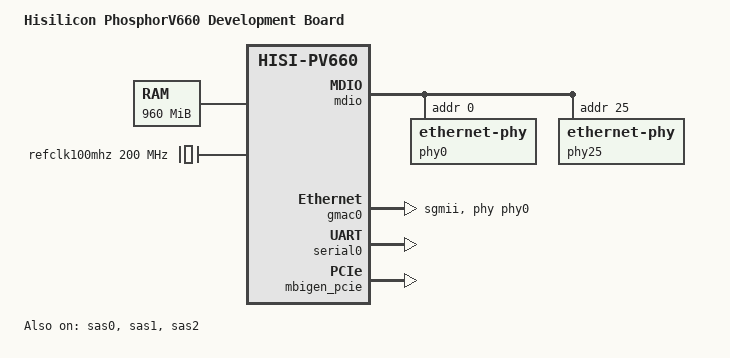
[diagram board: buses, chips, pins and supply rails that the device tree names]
/**
 * dts file for Hisilicon Hi1610
 *
 * Copyright (C) 2014, Hisilicon Ltd.
 *
 * This program is free software; you can redistribute it and/or modify
 * it under the terms of the GNU General Public License version 2 as
 * publishhed by the Free Software Foundation.
 *
 */

/dts-v1/;

/memreserve/ 0x00000000 0x00010000;

/ {
	#address-cells = <2>;
	#size-cells = <2>;
	model = "Hisilicon PhosphorV660 Development Board";
	compatible = "hisilicon,hip05-D02", "hisilicon,hisi-pv660";
	interrupt-parent = <&gic>;

	cpus {
		#address-cells = <1>;
		#size-cells = <0>;

		cpu@10000 {
			device_type = "cpu";
			compatible = "arm,armv8";
			reg = <0x10000>;
			enable-method = "spin-table";
			cpu-release-addr = <0x0 0xfff8>;
		};

		cpu@10001 {
			device_type = "cpu";
			compatible = "arm,armv8";
			reg = <0x10001>;
			enable-method = "spin-table";
			cpu-release-addr = <0x0 0xfff8>;
		};

		cpu@10002 {
			device_type = "cpu";
			compatible = "arm,armv8";
			reg = <0x10002>;
			enable-method = "spin-table";
			cpu-release-addr = <0x0 0xfff8>;
		};

		cpu@10003 {
			device_type = "cpu";
			compatible = "arm,armv8";
			reg = <0x10003>;
			enable-method = "spin-table";
			cpu-release-addr = <0x0 0xfff8>;
		};

		cpu@10100 {
			device_type = "cpu";
			compatible = "arm,armv8";
			reg = <0x10100>;
			enable-method = "spin-table";
			cpu-release-addr = <0x0 0xfff8>;
		};

		cpu@10101 {
			device_type = "cpu";
			compatible = "arm,armv8";
			reg = <0x10101>;
			enable-method = "spin-table";
			cpu-release-addr = <0x0 0xfff8>;
		};

		cpu@10102 {
			device_type = "cpu";
			compatible = "arm,armv8";
			reg = <0x10102>;
			enable-method = "spin-table";
			cpu-release-addr = <0x0 0xfff8>;
		};

		cpu@10103 {
			device_type = "cpu";
			compatible = "arm,armv8";
			reg = <0x10103>;
			enable-method = "spin-table";
			cpu-release-addr = <0x0 0xfff8>;
		};

		cpu@10200 {
			device_type = "cpu";
			compatible = "arm,armv8";
			reg = <0x10200>;
			enable-method = "spin-table";
			cpu-release-addr = <0x0 0xfff8>;
		};

		cpu@10201 {
			device_type = "cpu";
			compatible = "arm,armv8";
			reg = <0x10201>;
			enable-method = "spin-table";
			cpu-release-addr = <0x0 0xfff8>;
		};

		cpu@10202 {
			device_type = "cpu";
			compatible = "arm,armv8";
			reg = <0x10202>;
			enable-method = "spin-table";
			cpu-release-addr = <0x0 0xfff8>;
		};

		cpu@10203 {
			device_type = "cpu";
			compatible = "arm,armv8";
			reg = <0x10203>;
			enable-method = "spin-table";
			cpu-release-addr = <0x0 0xfff8>;
		};

		cpu@10300 {
			device_type = "cpu";
			compatible = "arm,armv8";
			reg = <0x10300>;
			enable-method = "spin-table";
			cpu-release-addr = <0x0 0xfff8>;
		};

		cpu@10301 {
			device_type = "cpu";
			compatible = "arm,armv8";
			reg = <0x10301>;
			enable-method = "spin-table";
			cpu-release-addr = <0x0 0xfff8>;
		};

		cpu@10302 {
			device_type = "cpu";
			compatible = "arm,armv8";
			reg = <0x10302>;
			enable-method = "spin-table";
			cpu-release-addr = <0x0 0xfff8>;
		};

		cpu@10303 {
			device_type = "cpu";
			compatible = "arm,armv8";
			reg = <0x10303>;
			enable-method = "spin-table";
			cpu-release-addr = <0x0 0xfff8>;
		};

		cpu@20000 {
			device_type = "cpu";
			compatible = "arm,armv8";
			reg = <0x20000>;
			enable-method = "spin-table";
			cpu-release-addr = <0x0 0xfff8>;
		};

		cpu@20001 {
			device_type = "cpu";
			compatible = "arm,armv8";
			reg = <0x20001>;
			enable-method = "spin-table";
			cpu-release-addr = <0x0 0xfff8>;
		};

		cpu@20002 {
			device_type = "cpu";
			compatible = "arm,armv8";
			reg = <0x20002>;
			enable-method = "spin-table";
			cpu-release-addr = <0x0 0xfff8>;
		};

		cpu@20003 {
			device_type = "cpu";
			compatible = "arm,armv8";
			reg = <0x20003>;
			enable-method = "spin-table";
			cpu-release-addr = <0x0 0xfff8>;
		};

		cpu@20100 {
			device_type = "cpu";
			compatible = "arm,armv8";
			reg = <0x20100>;
			enable-method = "spin-table";
			cpu-release-addr = <0x0 0xfff8>;
		};

		cpu@20101 {
			device_type = "cpu";
			compatible = "arm,armv8";
			reg = <0x20101>;
			enable-method = "spin-table";
			cpu-release-addr = <0x0 0xfff8>;
		};

		cpu@20102 {
			device_type = "cpu";
			compatible = "arm,armv8";
			reg = <0x20102>;
			enable-method = "spin-table";
			cpu-release-addr = <0x0 0xfff8>;
		};

		cpu@20103 {
			device_type = "cpu";
			compatible = "arm,armv8";
			reg = <0x20103>;
			enable-method = "spin-table";
			cpu-release-addr = <0x0 0xfff8>;
		};

		cpu@20200 {
			device_type = "cpu";
			compatible = "arm,armv8";
			reg = <0x20200>;
			enable-method = "spin-table";
			cpu-release-addr = <0x0 0xfff8>;
		};

		cpu@20201 {
			device_type = "cpu";
			compatible = "arm,armv8";
			reg = <0x20201>;
			enable-method = "spin-table";
			cpu-release-addr = <0x0 0xfff8>;
		};

		cpu@20202 {
			device_type = "cpu";
			compatible = "arm,armv8";
			reg = <0x20202>;
			enable-method = "spin-table";
			cpu-release-addr = <0x0 0xfff8>;
		};

		cpu@20203 {
			device_type = "cpu";
			compatible = "arm,armv8";
			reg = <0x20203>;
			enable-method = "spin-table";
			cpu-release-addr = <0x0 0xfff8>;
		};

		cpu@20300 {
			device_type = "cpu";
			compatible = "arm,armv8";
			reg = <0x20300>;
			enable-method = "spin-table";
			cpu-release-addr = <0x0 0xfff8>;
		};

		cpu@20301 {
			device_type = "cpu";
			compatible = "arm,armv8";
			reg = <0x20301>;
			enable-method = "spin-table";
			cpu-release-addr = <0x0 0xfff8>;
		};

		cpu@20302 {
			device_type = "cpu";
			compatible = "arm,armv8";
			reg = <0x20302>;
			enable-method = "spin-table";
			cpu-release-addr = <0x0 0xfff8>;
		};

		cpu@20303 {
			device_type = "cpu";
			compatible = "arm,armv8";
			reg = <0x20303>;
			enable-method = "spin-table";
			cpu-release-addr = <0x0 0xfff8>;
		};

	};

	memory@0 {
		device_type = "memory";
		reg = <0x0 0x00000000 0x0 0x3c000000>;
	};

	gic: interrupt-controller@6d000000 {
		compatible = "hisilicon,gic-v3";
		#interrupt-cells = <3>;
		#address-cells = <2>;
		#size-cells = <2>;
		ranges;
		interrupt-controller;
		#redistributor-regions = <2>;
		redistributor-stride = <0x0 0x30000>;
		reg = <0x0 0x6d000000 0x0 0x10000>,	/* GICD */
		      <0x0 0x6d100000 0x0 0x300000>,	/* GICR c*/
		      <0x0 0x4d100000 0 0x300000>,      /* GICR a */
		      <0x0 0xfe000000 0x0 0x10000>,	/* GICC */
		      <0x0 0xfe010000 0x0 0x10000>,     /* GICH */
		      <0x0 0xfe020000 0x0 0x10000>;     /* GICV */
		interrupts = <1 9 0xff04>;

		its_dsa: interrupt-controller@0xc6000000 {
			compatible = "arm,gic-v3-its";
			msi-controller;
			reg = <0x0 0xc6000000 0x0 0x1000000>;
		};
	};

	gic1: interrupt-controller@4d000000 {
		compatible = "hisilicon,gic-v3";
		#interrupt-cells = <3>;
		#address-cells = <2>;
		#size-cells = <2>;
		interrupt-controller;
		reg = <0x0 0x4d000000 0x0 0x10000>;
	};

	smmu_pcie {
		compatible = "arm,smmu-v3";
		reg = <0x0 0xa0040000 0x0 0x20000>;
		interrupt-parent  = <&mbigen_pcie>;
		interrupts = <0x40b0c 3 39 7>,
				<0x40b0c 3 40 7>,
				<0x40b0c 3 41 7>;
		interrupt-names = "EVENTQ", "GERROR", "PIRQ";
		smmu-cb-memtype = <0x0 0x1>,
				  <0x40040 0x1>;
	};

	smmu_dsa {
		compatible = "arm,smmu-v3";
		reg = <0x0 0xc0040000 0x0 0x20000>;
		interrupt-parent  = <&mbigen_dsa>;
		interrupts = <0x40b20 3 76 6>,
				<0x40b20 3 77 6>,
				<0x40b20 3 78 6>;
		interrupt-names = "EVENTQ", "GERROR", "PIRQ";
		smmu-cb-memtype = <0x0 0x1>,
				  <0x400000 0x1>;
	};

	smmu_alg {
		compatible = "arm,smmu-v3";
		reg = <0x0 0xd0040000 0x0 0x20000>;
		interrupt-parent  = <&mbigen_alg>;
		interrupts = <0x40b1b 3 28 6>,
				<0x40b1b 3 29 6>,
				<0x40b1b 3 30 6>;
		interrupt-names = "EVENTQ", "GERROR", "PIRQ";
		smmu-cb-memtype = <0x0 0x1>;
	};

	timer {
		compatible = "arm,armv8-timer";
		interrupts = <1 13 4>,
			     <1 14 4>,
			     <1 11 4>,
			     <1 10 4>;
	};

	sas0: sas@c3000000 {
		compatible = "hisilicon,sas-core-v2";
		core-id = <0>;
		reg = <0 0xc3000000 0 0x10000>,
			<0x0 0xc0000000 0x0 0x10000>;
		reset-reg = <0xa60>;
		clock-reg = <0x338>;
		queue-count = <16>;
		phy-count = <8>;
		#interrupt-cells = <2>;
		dma-coherent;
		interrupt-parent = <&mbigen_dsa>;
		interrupts = <0x40900 128 0 1>,
		<0x40900 128 1 1>,
		<0x40900 128 2 1>,
		<0x40900 128 3 1>,
		<0x40900 128 4 1>,
		<0x40900 128 5 1>,
		<0x40900 128 6 1>,
		<0x40900 128 7 1>,
		<0x40900 128 8 1>,
		<0x40900 128 9 1>,
		<0x40900 128 10 1>,
		<0x40900 128 11 1>,
		<0x40900 128 12 1>,
		<0x40900 128 13 1>,
		<0x40900 128 14 1>,
		<0x40900 128 15 1>,
		<0x40900 128 16 1>,
		<0x40900 128 17 1>,
		<0x40900 128 18 1>,
		<0x40900 128 19 1>,
		<0x40900 128 20 1>,
		<0x40900 128 21 1>,
		<0x40900 128 22 1>,
		<0x40900 128 23 1>,
		<0x40900 128 24 1>,
		<0x40900 128 25 1>,
		<0x40900 128 26 1>,
		<0x40900 128 27 1>,
		<0x40900 128 28 1>,
		<0x40900 128 29 1>,
		<0x40900 128 30 1>,
		<0x40900 128 31 1>,
		<0x40900 128 32 1>,
		<0x40900 128 33 1>,
		<0x40900 128 34 1>,
		<0x40900 128 35 1>,
		<0x40900 128 36 1>,
		<0x40900 128 37 1>,
		<0x40900 128 38 1>,
		<0x40900 128 39 1>,
		<0x40900 128 40 1>,
		<0x40900 128 41 1>,
		<0x40900 128 42 1>,
		<0x40900 128 43 1>,
		<0x40900 128 44 1>,
		<0x40900 128 45 1>,
		<0x40900 128 46 1>,
		<0x40900 128 47 1>,
		<0x40900 128 48 1>,
		<0x40900 128 49 1>,
		<0x40900 128 50 1>,
		<0x40900 128 51 1>,
		<0x40900 128 52 1>,
		<0x40900 128 53 1>,
		<0x40900 128 54 1>,
		<0x40900 128 55 1>,
		<0x40900 128 56 1>,
		<0x40900 128 57 1>,
		<0x40900 128 58 1>,
		<0x40900 128 59 1>,
		<0x40900 128 60 1>,
		<0x40900 128 61 1>,
		<0x40900 128 62 1>,
		<0x40900 128 63 1>,
		<0x40900 128 64 1>,
		<0x40900 128 65 1>,
		<0x40900 128 66 1>,
		<0x40900 128 67 1>,
		<0x40900 128 68 1>,
		<0x40900 128 69 1>,
		<0x40900 128 70 1>,
		<0x40900 128 71 1>,
		<0x40900 128 72 1>,
		<0x40900 128 73 1>,
		<0x40900 128 74 1>,
		<0x40900 128 75 1>,
		<0x40900 128 76 1>,
		<0x40900 128 77 1>,
		<0x40900 128 78 1>,
		<0x40900 128 79 1>,
		<0x40900 128 80 1>,
		<0x40900 128 81 1>,
		<0x40900 128 82 1>,
		<0x40900 128 83 1>,
		<0x40900 128 84 1>,
		<0x40900 128 85 1>,
		<0x40900 128 86 1>,
		<0x40900 128 87 1>,
		<0x40900 128 88 1>,
		<0x40900 128 89 1>,
		<0x40900 128 90 1>,
		<0x40900 128 91 1>,
		<0x40900 128 92 1>,
		<0x40900 128 93 1>,
		<0x40900 128 94 1>,
		<0x40900 128 95 1>,
		<0x40900 128 25 5>,
		<0x40900 128 26 5>,
		<0x40900 128 27 5>,
		<0x40900 128 28 5>,
		<0x40900 128 29 5>,
		<0x40900 128 30 5>,
		<0x40900 128 31 5>,
		<0x40900 128 32 5>,
		<0x40900 128 33 5>,
		<0x40900 128 34 5>,
		<0x40900 128 35 5>,
		<0x40900 128 36 5>,
		<0x40900 128 37 5>,
		<0x40900 128 38 5>,
		<0x40900 128 39 5>,
		<0x40900 128 40 5>,
		<0x40900 128 41 5>,
		<0x40900 128 42 5>,
		<0x40900 128 43 5>,
		<0x40900 128 44 5>,
		<0x40900 128 45 5>,
		<0x40900 128 46 5>,
		<0x40900 128 47 5>,
		<0x40900 128 48 5>,
		<0x40900 128 49 5>,
		<0x40900 128 50 5>,
		<0x40900 128 51 5>,
		<0x40900 128 52 5>,
		<0x40900 128 53 5>,
		<0x40900 128 54 5>,
		<0x40900 128 55 5>,
		<0x40900 128 56 5>;
		status = "okay";
	};

	sas1: sas@a2000000 {
		compatible = "hisilicon,sas-core-v2";
		core-id = <1>;
		reg = <0 0xa2000000 0 0x10000>,
			<0x0 0xb0000000 0x0 0x10000>;
		reset-reg = <0xa18>;
		clock-reg = <0x318>;
		queue-count = <16>;
		phy-count = <8>;
		#interrupt-cells = <2>;
		dma-coherent;
		interrupt-parent = <&mbigen_pcie>;
		interrupts = <0x40000 128 0 1>,
		<0x40000 128 1 1>,
		<0x40000 128 2 1>,
		<0x40000 128 3 1>,
		<0x40000 128 4 1>,
		<0x40000 128 5 1>,
		<0x40000 128 6 1>,
		<0x40000 128 7 1>,
		<0x40000 128 8 1>,
		<0x40000 128 9 1>,
		<0x40000 128 10 1>,
		<0x40000 128 11 1>,
		<0x40000 128 12 1>,
		<0x40000 128 13 1>,
		<0x40000 128 14 1>,
		<0x40000 128 15 1>,
		<0x40000 128 16 1>,
		<0x40000 128 17 1>,
		<0x40000 128 18 1>,
		<0x40000 128 19 1>,
		<0x40000 128 20 1>,
		<0x40000 128 21 1>,
		<0x40000 128 22 1>,
		<0x40000 128 23 1>,
		<0x40000 128 24 1>,
		<0x40000 128 25 1>,
		<0x40000 128 26 1>,
		<0x40000 128 27 1>,
		<0x40000 128 28 1>,
		<0x40000 128 29 1>,
		<0x40000 128 30 1>,
		<0x40000 128 31 1>,
		<0x40000 128 32 1>,
		<0x40000 128 33 1>,
		<0x40000 128 34 1>,
		<0x40000 128 35 1>,
		<0x40000 128 36 1>,
		<0x40000 128 37 1>,
		<0x40000 128 38 1>,
		<0x40000 128 39 1>,
		<0x40000 128 40 1>,
		<0x40000 128 41 1>,
		<0x40000 128 42 1>,
		<0x40000 128 43 1>,
		<0x40000 128 44 1>,
		<0x40000 128 45 1>,
		<0x40000 128 46 1>,
		<0x40000 128 47 1>,
		<0x40000 128 48 1>,
		<0x40000 128 49 1>,
		<0x40000 128 50 1>,
		<0x40000 128 51 1>,
		<0x40000 128 52 1>,
		<0x40000 128 53 1>,
		<0x40000 128 54 1>,
		<0x40000 128 55 1>,
		<0x40000 128 56 1>,
		<0x40000 128 57 1>,
		<0x40000 128 58 1>,
		<0x40000 128 59 1>,
		<0x40000 128 60 1>,
		<0x40000 128 61 1>,
		<0x40000 128 62 1>,
		<0x40000 128 63 1>,
		<0x40000 128 64 1>,
		<0x40000 128 65 1>,
		<0x40000 128 66 1>,
		<0x40000 128 67 1>,
		<0x40000 128 68 1>,
		<0x40000 128 69 1>,
		<0x40000 128 70 1>,
		<0x40000 128 71 1>,
		<0x40000 128 72 1>,
		<0x40000 128 73 1>,
		<0x40000 128 74 1>,
		<0x40000 128 75 1>,
		<0x40000 128 76 1>,
		<0x40000 128 77 1>,
		<0x40000 128 78 1>,
		<0x40000 128 79 1>,
		<0x40000 128 80 1>,
		<0x40000 128 81 1>,
		<0x40000 128 82 1>,
		<0x40000 128 83 1>,
		<0x40000 128 84 1>,
		<0x40000 128 85 1>,
		<0x40000 128 86 1>,
		<0x40000 128 87 1>,
		<0x40000 128 88 1>,
		<0x40000 128 89 1>,
		<0x40000 128 90 1>,
		<0x40000 128 91 1>,
		<0x40000 128 92 1>,
		<0x40000 128 93 1>,
		<0x40000 128 94 1>,
		<0x40000 128 95 1>,
		<0x40000 128 0 5>,
		<0x40000 128 1 5>,
		<0x40000 128 2 5>,
		<0x40000 128 3 5>,
		<0x40000 128 4 5>,
		<0x40000 128 5 5>,
		<0x40000 128 6 5>,
		<0x40000 128 7 5>,
		<0x40000 128 8 5>,
		<0x40000 128 9 5>,
		<0x40000 128 10 5>,
		<0x40000 128 11 5>,
		<0x40000 128 12 5>,
		<0x40000 128 13 5>,
		<0x40000 128 14 5>,
		<0x40000 128 15 5>,
		<0x40000 128 16 5>,
		<0x40000 128 17 5>,
		<0x40000 128 18 5>,
		<0x40000 128 19 5>,
		<0x40000 128 20 5>,
		<0x40000 128 21 5>,
		<0x40000 128 22 5>,
		<0x40000 128 23 5>,
		<0x40000 128 24 5>,
		<0x40000 128 25 5>,
		<0x40000 128 26 5>,
		<0x40000 128 27 5>,
		<0x40000 128 28 5>,
		<0x40000 128 29 5>,
		<0x40000 128 31 5>,
		<0x40000 128 31 5>;
		status = "okay";
	};

	sas2: sas@a3000000 {
		compatible = "hisilicon,hi1610-sas-core";
		core-id = <2>;
		reg = <0 0xa3000000 0 0x10000>,
			<0 0xa0000000 0 0x10000>;
		reset-reg = <0xae0>;
		clock-reg = <0x3a8>;
		queue-count = <16>;
		phy-count = <8>;
		#interrupt-cells = <2>;
		dma-coherent;
		interrupt-parent = <&mbigen_pcie>;
		interrupts = <0x40040 128 0 2>,
		<0x40040 128 1 2>,
		<0x40040 128 2 2>,
		<0x40040 128 3 2>,
		<0x40040 128 4 2>,
		<0x40040 128 5 2>,
		<0x40040 128 6 2>,
		<0x40040 128 7 2>,
		<0x40040 128 8 2>,
		<0x40040 128 9 2>,
		<0x40040 128 10 2>,
		<0x40040 128 11 2>,
		<0x40040 128 12 2>,
		<0x40040 128 13 2>,
		<0x40040 128 14 2>,
		<0x40040 128 15 2>,
		<0x40040 128 16 2>,
		<0x40040 128 17 2>,
		<0x40040 128 18 2>,
		<0x40040 128 19 2>,
		<0x40040 128 20 2>,
		<0x40040 128 21 2>,
		<0x40040 128 22 2>,
		<0x40040 128 23 2>,
		<0x40040 128 24 2>,
		<0x40040 128 25 2>,
		<0x40040 128 26 2>,
		<0x40040 128 27 2>,
		<0x40040 128 28 2>,
		<0x40040 128 29 2>,
		<0x40040 128 30 2>,
		<0x40040 128 31 2>,
		<0x40040 128 32 2>,
		<0x40040 128 33 2>,
		<0x40040 128 34 2>,
		<0x40040 128 35 2>,
		<0x40040 128 36 2>,
		<0x40040 128 37 2>,
		<0x40040 128 38 2>,
		<0x40040 128 39 2>,
		<0x40040 128 40 2>,
		<0x40040 128 41 2>,
		<0x40040 128 42 2>,
		<0x40040 128 43 2>,
		<0x40040 128 44 2>,
		<0x40040 128 45 2>,
		<0x40040 128 46 2>,
		<0x40040 128 47 2>,
		<0x40040 128 48 2>,
		<0x40040 128 49 2>,
		<0x40040 128 50 2>,
		<0x40040 128 51 2>,
		<0x40040 128 52 2>,
		<0x40040 128 53 2>,
		<0x40040 128 54 2>,
		<0x40040 128 55 2>,
		<0x40040 128 56 2>,
		<0x40040 128 57 2>,
		<0x40040 128 58 2>,
		<0x40040 128 59 2>,
		<0x40040 128 60 2>,
		<0x40040 128 61 2>,
		<0x40040 128 62 2>,
		<0x40040 128 63 2>,
		<0x40040 128 64 2>,
		<0x40040 128 65 2>,
		<0x40040 128 66 2>,
		<0x40040 128 67 2>,
		<0x40040 128 68 2>,
		<0x40040 128 69 2>,
		<0x40040 128 70 2>,
		<0x40040 128 71 2>,
		<0x40040 128 72 2>,
		<0x40040 128 73 2>,
		<0x40040 128 74 2>,
		<0x40040 128 75 2>,
		<0x40040 128 76 2>,
		<0x40040 128 77 2>,
		<0x40040 128 78 2>,
		<0x40040 128 79 2>,
		<0x40040 128 80 2>,
		<0x40040 128 81 2>,
		<0x40040 128 82 2>,
		<0x40040 128 83 2>,
		<0x40040 128 84 2>,
		<0x40040 128 85 2>,
		<0x40040 128 86 2>,
		<0x40040 128 87 2>,
		<0x40040 128 88 2>,
		<0x40040 128 89 2>,
		<0x40040 128 90 2>,
		<0x40040 128 91 2>,
		<0x40040 128 92 2>,
		<0x40040 128 93 2>,
		<0x40040 128 94 2>,
		<0x40040 128 95 2>,
		<0x40040 128 32 5>,
		<0x40040 128 33 5>,
		<0x40040 128 34 5>,
		<0x40040 128 35 5>,
		<0x40040 128 36 5>,
		<0x40040 128 37 5>,
		<0x40040 128 38 5>,
		<0x40040 128 39 5>,
		<0x40040 128 40 5>,
		<0x40040 128 41 5>,
		<0x40040 128 42 5>,
		<0x40040 128 43 5>,
		<0x40040 128 44 5>,
		<0x40040 128 45 5>,
		<0x40040 128 46 5>,
		<0x40040 128 47 5>,
		<0x40040 128 48 5>,
		<0x40040 128 49 5>,
		<0x40040 128 50 5>,
		<0x40040 128 51 5>,
		<0x40040 128 52 5>,
		<0x40040 128 53 5>,
		<0x40040 128 54 5>,
		<0x40040 128 55 5>,
		<0x40040 128 56 5>,
		<0x40040 128 57 5>,
		<0x40040 128 58 5>,
		<0x40040 128 59 5>,
		<0x40040 128 60 5>,
		<0x40040 128 61 5>,
		<0x40040 128 62 5>,
		<0x40040 128 63 5>;
		status = "okay";
	};

	mdio {
		compatible = "hisilicon, hip05-mdio";
		reg = <0x0 0x603c0000 0x0 0x1000>;
		#address-cells = <0x1>;
		#size-cells = <0x0>;

		phy0: ethernet-phy@0 {
			compatile = "ethernet-phy-ieee802.3-c22";
			reg = <0>;
			max-speed = <10>;
		};

		phy25: ethernet-phy@25 {
			compatile = "ethernet-phy-ieee802.3-c22";
			reg = <25>;
			max-speed = <10>;
		};
	};

	ppe: ppe@c2000000 {
		compatible = "hisilicon, hip05-ppe", "syscon";
		reg = <0 0xc2000000 0 0x1000>;
	};

	ge: ge@c2001000 {
		compatible = "hisilicon, hip05-ge", "syscon";
		reg = <0 0xc2001000 0 0x1000>;
	};

	gmac0: ethernet@c2080000 {
		compatible = "hisilicon, hip05-mac";
		#address-cells = <1>;
		#size-cells = <0>;
		reg = <0 0xc2080000 0 0x20000>,
		      <0 0xc0000000 0 0x1000>;
		interrupt-parent  = <&mbigen_dsa>;
		interrupts = <0x40b1c 9 0 6>, /* rx irq */
			     <0x40b1c 9 1 6>; /* tx irq */

		phy-mode = "sgmii";
		mac-address = [11 11 11 11 11 11];
		phy-handle = <&phy0>;
		ppe-handle = <&ppe 0>;
		ge-handle = <&ge 10 1>;
		dma-coherent;
	};

	pmu {
		compatible = "arm,armv8-pmuv3";
		interrupts = <1 7 4>;
	};

	peripherals {
		compatible = "simple-bus";
		#address-cells = <1>;
		#size-cells = <1>;
		ranges = <0x0 0x00000000 0x0 0xffffffff>;

		refclk100mhz: refclk100mhz {
			compatible = "fixed-clock";
			#clock-cells = <0>;
			clock-frequency = <200000000>;
		};

		serial0: uart@60300000 {
			compatible = "snps,dw-apb-uart";
			reg = <0x60300000 0x10000>;
			interrupts = <0 317 4>;
			clocks = <&refclk100mhz>;
			clock-names = "apb_pclk";
			reg-shift = <2>;
		};

		mbigen_dsa: interrupt-controller@c0080000 {
			compatible = "hisilicon,mbigen-v2";
			msi-parent = <&its_dsa>;
			interrupt-controller;
			#interrupt-cells = <4>;
			reg = <0xc0080000 0x10000>;
		};

		mbigen_pcie: interrupt-controller@a0080000 {
			compatible = "hisilicon,mbigen-v2";
			msi-parent = <&its_dsa>;
			interrupt-controller;
			#interrupt-cells = <4>;
			reg = <0xa0080000 0x10000>;
		};

		mbigen_alg: interrupt-controller@d0080000 {
			compatible = "hisilicon,mbigen-v2";
			msi-parent = <&its_dsa>;
			interrupt-controller;
			#interrupt-cells = <4>;
			reg = <0xd0080000 0x10000>;
		};

	};

/*	/include/ "hisi_hi1610_pcie_evb.dtsi" */

	chosen {
		bootargs = "rdinit=/init console=ttyS0,115200 earlycon=uart8250,mmio32,0x60300000";
		linux,initrd-start = <0x7000000>;
		linux,initrd-end = <0xa000000>;
	};
};
